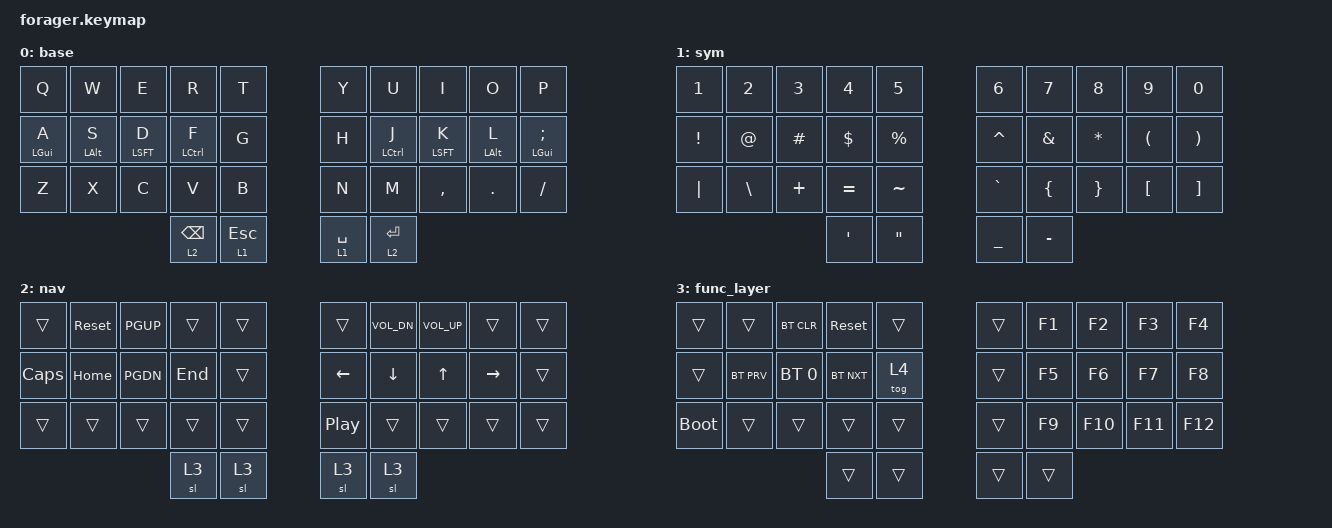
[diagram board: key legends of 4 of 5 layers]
#include <behaviors.dtsi>
#include <dt-bindings/zmk/keys.h>
#include <dt-bindings/zmk/bt.h>
#include <dt-bindings/zmk/outputs.h>

#define BASE 0
#define NAV  1
#define SYM  2
#define ADJ  3

/ {
    behaviors {                                         
        hm: homerow_mods {                                                                                             
            compatible = "zmk,behavior-hold-tap";                                                                      
            label = "HOMEROW_MODS";                                                                                    
            #binding-cells = <2>;                                                                                      
            tapping-term-ms = <200>;
            quick-tap-ms = <0>;                                                                                        
            flavor = "tap-preferred";                                                                                                                                                                                                          
            bindings = <&kp>, <&kp>;                                                                                                                                                                                                           
        };                                                                                                             
    };                                                                                                                 
                                                                                                                       
    combos {                                                                                                           
        compatible = "zmk,combos";                         
        combo_del {              
            timeout-ms = <50>;                                                                                         
            key-positions = <21 23>;                                                                                   
            bindings = <&kp DEL>;                                                                                      
            layers = <0>;                                                                                              
        };                                                                                                             
        combo_tab {                                        
            timeout-ms = <50>;                                                                                         
            key-positions = <26 28>;                       
            bindings = <&kp TAB>;                       
            layers = <0>;                                                                                              
        };                                                                                                             
        combo_caps {                                                                                                   
            timeout-ms = <50>;                                                                                         
            key-positions = <20 29>;
            bindings = <&kp CAPS>;                                                                                     
            layers = <0>;                                                                                                                                                                                                                      
        };                                                                                                                                                                                                                                     
    };

    keymap {
        compatible = "zmk,keymap";

        base {                   
            bindings = <                                                                                               
                &kp Q &kp W &kp E &kp R &kp T &kp Y &kp U &kp I &kp O &kp P                             
                                                                                                                       
                &hm LGUI A &hm LALT S &hm LSFT D &hm LCTL F &kp G             
                                    &kp H &hm LCTL J &hm LSFT K &hm LALT L &hm LGUI SEMI

                &kp Z &kp X &kp C &kp V &kp B   &kp N &kp M  &kp COMMA &kp DOT &kp FSLH

                &lt 2 BSPC &lt 1 ESC &lt 1 SPC &lt 2 RET
            >;
        };

        sym {
            bindings = <
                &kp N1    &kp N2    &kp N3    &kp N4      &kp N5      &kp N6    &kp N7    &kp N8    &kp N9     &kp N0
                &kp EXCL  &kp AT    &kp HASH  &kp DOLLAR  &kp PRCNT   &kp CARET &kp AMPS  &kp STAR  &kp LPAR   &kp RPAR
                &kp PIPE  &kp BSLH  &kp PLUS  &kp EQUAL   &kp TILDE   &kp GRAVE &kp LBRC  &kp RBRC  &kp LBKT   &kp RBKT
                                                    &kp SQT &kp DQT &kp UNDER &kp MINUS
            >;
        };

        nav {
            bindings = <
                &trans &sys_reset &kp PGUP &trans &trans       &trans &kp C_VOL_DN &kp C_VOL_UP &trans &trans
                &kp CAPS &kp HOME &kp PGDN &kp END &trans      &kp LEFT &kp DOWN &kp UP &kp RIGHT &trans
                &trans &trans &trans &trans &trans &kp C_PP    &trans &trans &trans &trans
                                       &sl 3 &sl 3                 &sl 3 &sl 3
            >;
        };

        func_layer {
            bindings = <
                &trans &trans      &bt BT_CLR    &sys_reset     &trans     &trans  &kp F1   &kp F2   &kp F3 &kp F4
                &trans &bt BT_PRV  &bt BT_SEL 0  &bt BT_NXT &tog 4     &trans  &kp F5   &kp F6   &kp F7 &kp F8
                &bootloader &trans &trans        &trans     &trans     &trans  &kp F9   &kp F10   &kp F11 &kp F12
                                      &trans     &trans     &trans  &trans
            >;
        };

        gaming_layer {
// -----------------------------------------------------------------------------------------
// |  Q  |  W  |  E  |  R  |  T   |  Y  |  U   |  I  |  O  |  P  |
// |  A  |  S  |  D  |  F  |  G   |  H  |  J   |  K  |  L  |  ;  |
// |  Z  |  X  |  C  |  V  |  B   |  N  |  M   |  ,  |  .  |  /  |
//             | DEL | BSP |  ECS | ENT | SPC  | TAB |
                     bindings = <
&kp Q &kp W &kp E &kp R &kp T   &kp Y &kp U  &kp I   &kp O   &kp P
&kp A &kp S &kp D &kp F &kp G   &kp H &kp J  &kp K   &kp L   &kp SEMI
&kp Z &kp X &kp C &kp V &kp B   &kp N &kp M  &kp COMMA &kp DOT &kp FSLH
      &kp DEL &kp BSPC &kp ESC  &kp RET &kp SPC &tog 4
                        >;
                };
        
    };
};

&lt {
    // require-prior-idle-ms = <100>;
    tapping-term-ms = <150>;
    quick-tap-ms = <200>;
};

&mt {
    quick-tap-ms = <200>;
};

&sk {
    release-after-ms = <500>;
    quick-release;
};
